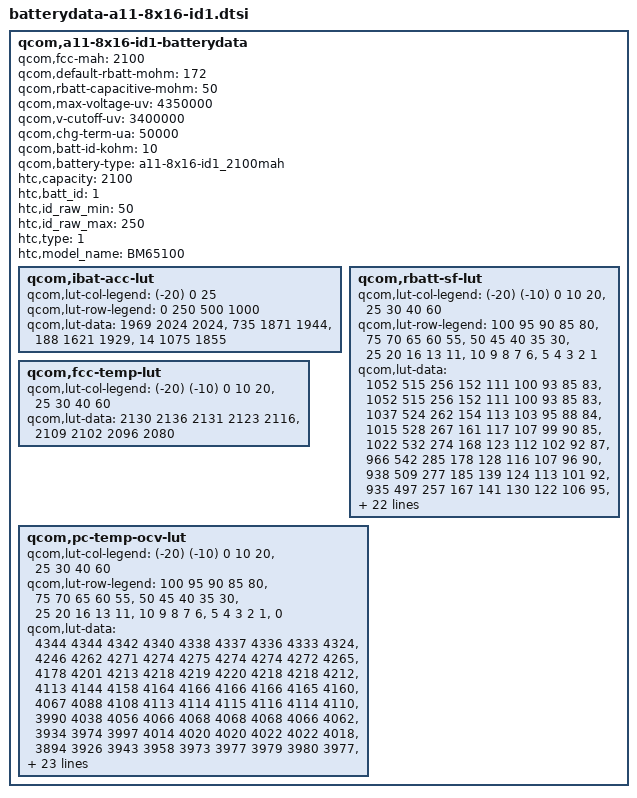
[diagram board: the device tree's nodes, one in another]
/* Copyright (c) 2013, The Linux Foundation. All rights reserved.
 *
 * This program is free software; you can redistribute it and/or modify
 * it under the terms of the GNU General Public License version 2 and
 * only version 2 as published by the Free Software Foundation.
 *
 * This program is distributed in the hope that it will be useful,
 * but WITHOUT ANY WARRANTY; without even the implied warranty of
 * MERCHANTABILITY or FITNESS FOR A PARTICULAR PURPOSE.  See the
 * GNU General Public License for more details.
 */

qcom,a11-8x16-id1-batterydata {
	qcom,fcc-mah = <2100>;
	qcom,default-rbatt-mohm = <172>;
	qcom,rbatt-capacitive-mohm = <50>;
	qcom,max-voltage-uv = <4350000>;
	qcom,v-cutoff-uv = <3400000>;
	qcom,chg-term-ua = <50000>;
	qcom,batt-id-kohm = <10>;
	qcom,battery-type = "a11-8x16-id1_2100mah";
	htc,capacity = <2100>;
	htc,batt_id = <1>;
	htc,id_raw_min = <50>;
	htc,id_raw_max = <250>;
	htc,type = <1>;
	htc,model_name = "BM65100";

	qcom,ibat-acc-lut {
		qcom,lut-col-legend = <(-20) 0 25>;
		qcom,lut-row-legend = <0 250 500 1000>;
		qcom,lut-data = <1969 2024 2024>,
				<735 1871 1944>,
				<188 1621 1929>,
				<14 1075 1855>;
	};

	qcom,rbatt-sf-lut {
		qcom,lut-col-legend = <(-20) (-10) 0 10 20>,
				<25 30 40 60>;
		qcom,lut-row-legend = <100 95 90 85 80>,
				<75 70 65 60 55>,
				<50 45 40 35 30>,
				<25 20 16 13 11>,
				<10 9 8 7 6>,
				<5 4 3 2 1>;
		qcom,lut-data = <1052 515 256 152 111 100 93 85 83>,
				<1052 515 256 152 111 100 93 85 83>,
				<1037 524 262 154 113 103 95 88 84>,
				<1015 528 267 161 117 107 99 90 85>,
				<1022 532 274 168 123 112 102 92 87>,
				<966 542 285 178 128 116 107 96 90>,
				<938 509 277 185 139 124 113 101 92>,
				<935 497 257 167 141 130 122 106 95>,
				<938 503 255 157 121 113 109 102 94>,
				<952 505 255 153 113 102 97 88 84>,
				<979 515 260 156 115 103 98 89 86>,
				<1018 530 265 160 119 106 101 93 88>,
				<1065 551 273 164 122 110 104 96 92>,
				<1121 594 285 170 127 114 107 97 88>,
				<1186 644 301 175 124 112 104 92 87>,
				<1260 704 317 177 121 107 99 90 87>,
				<1376 773 358 180 119 106 97 87 84>,
				<1601 833 413 208 134 117 105 95 89>,
				<1862 856 448 237 152 133 119 104 96>,
				<1958 823 438 241 162 143 128 113 102>,
				<2153 849 450 249 166 145 130 115 106>,
				<2547 883 470 259 171 149 133 118 109>,
				<3178 922 491 270 177 153 137 121 111>,
				<4120 977 516 285 187 160 142 126 115>,
				<5359 1130 555 310 202 172 152 133 120>,
				<6931 1410 606 344 226 191 167 144 127>,
				<8901 2116 676 387 253 215 185 157 136>,
				<11444 3105 824 449 288 243 209 174 148>,
				<15335 4516 1461 588 363 293 252 205 171>,
				<20300 7100 2777 1176 654 437 367 291 237>;
	};

	qcom,fcc-temp-lut {
		qcom,lut-col-legend = <(-20) (-10) 0 10 20>,
				<25 30 40 60>;
		qcom,lut-data = <2130 2136 2131 2123 2116>,
				<2109 2102 2096 2080>;
	};

	qcom,pc-temp-ocv-lut {
		qcom,lut-col-legend = <(-20) (-10) 0 10 20>,
				<25 30 40 60>;
		qcom,lut-row-legend = <100 95 90 85 80>,
				<75 70 65 60 55>,
				<50 45 40 35 30>,
				<25 20 16 13 11>,
				<10 9 8 7 6>,
				<5 4 3 2 1>,
				<0>;
		qcom,lut-data = <4344 4344 4342 4340 4338 4337 4336 4333 4324>,
				<4246 4262 4271 4274 4275 4274 4274 4272 4265>,
				<4178 4201 4213 4218 4219 4220 4218 4218 4212>,
				<4113 4144 4158 4164 4166 4166 4166 4165 4160>,
				<4067 4088 4108 4113 4114 4115 4116 4114 4110>,
				<3990 4038 4056 4066 4068 4068 4068 4066 4062>,
				<3934 3974 3997 4014 4020 4020 4022 4022 4018>,
				<3894 3926 3943 3958 3973 3977 3979 3980 3977>,
				<3856 3888 3904 3912 3918 3922 3926 3930 3928>,
				<3830 3852 3869 3876 3878 3880 3882 3882 3883>,
				<3810 3821 3839 3846 3850 3852 3852 3854 3854>,
				<3792 3798 3814 3822 3826 3827 3828 3830 3829>,
				<3774 3781 3790 3801 3805 3806 3807 3808 3808>,
				<3756 3766 3773 3782 3786 3788 3788 3786 3779>,
				<3736 3750 3754 3763 3764 3764 3764 3760 3749>,
				<3710 3730 3728 3733 3732 3732 3732 3728 3716>,
				<3676 3706 3705 3700 3694 3692 3690 3686 3678>,
				<3632 3678 3688 3688 3686 3684 3682 3678 3666>,
				<3578 3644 3663 3669 3668 3670 3670 3666 3650>,
				<3521 3596 3622 3632 3636 3638 3639 3636 3622>,
				<3486 3564 3596 3610 3613 3616 3617 3614 3602>,
				<3448 3530 3569 3584 3587 3591 3592 3588 3575>,
				<3410 3494 3538 3554 3556 3560 3562 3558 3546>,
				<3371 3456 3502 3518 3520 3525 3526 3524 3512>,
				<3334 3418 3461 3480 3482 3488 3488 3487 3475>,
				<3298 3374 3420 3440 3444 3450 3450 3449 3438>,
				<3263 3330 3377 3398 3404 3409 3410 3408 3398>,
				<3230 3284 3326 3348 3353 3360 3359 3358 3344>,
				<3192 3232 3264 3282 3286 3292 3290 3289 3272>,
				<3120 3162 3184 3188 3182 3196 3188 3188 3165>,
				<3000 3000 3000 3000 3000 3000 3000 3000 3000>;
	};
};
